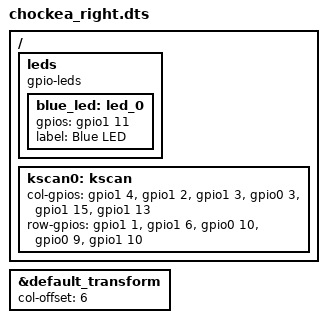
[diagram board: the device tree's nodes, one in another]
/*
 * Copyright (c) 2021 Thys de Wet (vattern)
 *
 * SPDX-License-Identifier: MIT
 */

/dts-v1/;
#include <nordic/nrf52840_qiaa.dtsi>
#include <dt-bindings/zmk/matrix_transform.h>
#include "chockea.dtsi"
&default_transform {
  col-offset = <6>;
};

/ {
leds {
  compatible = "gpio-leds";
  blue_led: led_0 {
    gpios = <&gpio1 11 GPIO_ACTIVE_HIGH>;
    label = "Blue LED";
  };
};


kscan0: kscan {
  col-gpios
      = <&gpio1 4   (GPIO_ACTIVE_HIGH | GPIO_PULL_DOWN)>
      , <&gpio1 2   (GPIO_ACTIVE_HIGH | GPIO_PULL_DOWN)>
      , <&gpio1 3   (GPIO_ACTIVE_HIGH | GPIO_PULL_DOWN)>
      , <&gpio0 3   (GPIO_ACTIVE_HIGH | GPIO_PULL_DOWN)>
      , <&gpio1 15  (GPIO_ACTIVE_HIGH | GPIO_PULL_DOWN)>
      , <&gpio1 13  (GPIO_ACTIVE_HIGH | GPIO_PULL_DOWN)>
      ;
  row-gpios
      = <&gpio1 1   GPIO_ACTIVE_HIGH>
      , <&gpio1 6   GPIO_ACTIVE_HIGH>
      , <&gpio0 10  GPIO_ACTIVE_HIGH>
      , <&gpio0 9   GPIO_ACTIVE_HIGH>
      , <&gpio1 10  GPIO_ACTIVE_HIGH>
      ;
    };
};
